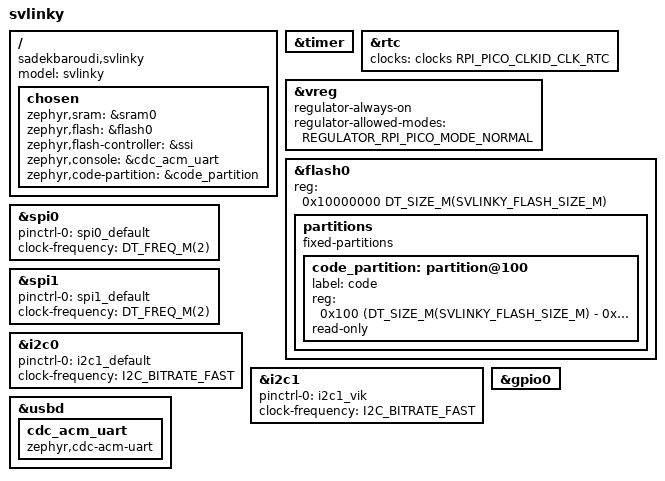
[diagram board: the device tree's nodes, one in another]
/*
 * Copyright (c) 2021 Yonatan Schachter
 *
 * SPDX-License-Identifier: Apache-2.0
 */

/dts-v1/;

#include <raspberrypi/rpi_pico/rp2040.dtsi>
#include <arm/raspberrypi/rp2040-boot-mode-retention.dtsi>
#include "svlinky-pinctl.dtsi"
#include <freq.h>

/ {
	model = "svlinky";
	compatible = "sadekbaroudi,svlinky", "raspberrypi,rp2040";

	chosen {
		zephyr,sram = &sram0;
		zephyr,flash = &flash0;
		zephyr,flash-controller = &ssi;
		zephyr,console = &cdc_acm_uart;
		zephyr,code-partition = &code_partition;
	};
};

&timer {
	status = "okay";
};

&rtc {
	clocks = <&clocks RPI_PICO_CLKID_CLK_RTC>;
	status = "okay";
};

&vreg {
	regulator-always-on;
	regulator-allowed-modes = <REGULATOR_RPI_PICO_MODE_NORMAL>;
};

#define SVLINKY_FLASH_SIZE_M 4

&flash0 {
	/* 8MB of flash minus the 0x100 used for
	 * the second stage bootloader
	 */
	reg = <0x10000000 DT_SIZE_M(SVLINKY_FLASH_SIZE_M)>;

	partitions {
		compatible = "fixed-partitions";
		#address-cells = <1>;
		#size-cells = <1>;

		/*
		 * Start at the beginning of usable flash, SVLINKY_FLASH_SIZE_M MB minus the
		 * second stage space and the 16 KiB reserved for settings
		 */
		code_partition: partition@100 {
			label = "code";
			reg = <0x100 (DT_SIZE_M(SVLINKY_FLASH_SIZE_M) - 0x100)>;
			read-only;
		};
	};
};

&spi0 {
	pinctrl-0 = <&spi0_default>;
	pinctrl-names = "default";
	clock-frequency = <DT_FREQ_M(2)>;
};

&spi1 {
	pinctrl-0 = <&spi1_default>;
	pinctrl-names = "default";
	clock-frequency = <DT_FREQ_M(2)>;
};

&i2c0 {
	pinctrl-0 = <&i2c1_default>;
	pinctrl-names = "default";
	clock-frequency = <I2C_BITRATE_FAST>;
};

&i2c1 {
	pinctrl-0 = <&i2c1_vik>;
	pinctrl-names = "default";
	clock-frequency = <I2C_BITRATE_FAST>;
};

&gpio0 {
	status = "okay";
};

zephyr_udc0: &usbd {
	status = "okay";
	cdc_acm_uart: cdc_acm_uart {
		compatible = "zephyr,cdc-acm-uart";
	};
};
